# R7KA8T2AD register map
Vendor: Renesas Electronics Corporation; Series: RA8; File version: 1.10.02
CPU: CM85 r0p2, little endian, MPU, FPU, VTOR, 4 interrupt priority bits, 96 interrupts
Registers are 32-bit, read-write, reset 0x0 unless marked. A register's access mark holds for its fields unless they carry their own. Offsets are from the block's base; [hi:lo] are bit positions; <NAME> marks a mode.

## ULPT0
Base 0x40220000
Same registers: ULPT1 0x40220100, ULPT0_NS 0x50220000, ULPT1_NS 0x50220100
0x00 ULPTCNT reset 0xFFFFFFFF — ULPT Counter Register
  [31:0] ULPTCNT — Setting range : 0x00000000 to 0xFFFFFFFF
0x04 ULPTCMA reset 0xFFFFFFFF — ULPT Compare Match A Register
  [31:0] ULPTCMA — 32-bit Compare Match A Data
0x08 ULPTCMB reset 0xFFFFFFFF — ULPT Compare Match B Register
  [31:0] ULPTCMB — 32-bit Compare Match B Data
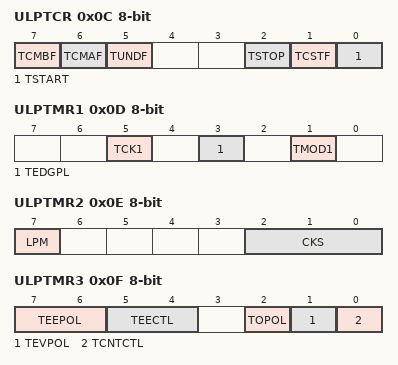
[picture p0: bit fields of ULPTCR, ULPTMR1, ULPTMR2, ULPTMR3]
0x0C ULPTCR 8-bit — ULPT Control Register
  [7] TCMBF — Compare Match B Flag
    0=Not matched (counter ≠ ULPTCMB[31:0]); 1=Matched (counter = ULPTCMB[31:0])
  [6] TCMAF — Compare Match A Flag
    0=Not matched (counter ≠ ULPTCMA[31:0]); 1=Matched (counter = ULPTCMA[31:0])
  [5] TUNDF — Underflow Flag
    0=No underflow occurred (counter ≠ 0x00000000); 1=Underflow occurred (counter = 0x00000000)
  [2] TSTOP wo — Counter Forcible Stop
    0=Writing is invalid; 1=Stop the counter forcibly
  [1] TCSTF ro — Counter Status Flag
    0=Counter stopped; 1=Counter running
  [0] TSTART — Counter Start
    0=Stop the counter; 1=Start the counter
0x0D ULPTMR1 8-bit — ULPT Mode Register 1
  [5] TCK1 — Count Source
    0=Divided clock specified by the ULPTMR2.CKS[2:0] bits (ULPTLCLK); 1=Divided clock specified by the ULPTMR2.CKS[2:0] bits (ULPTSCLK)
  [3] TEDGPL — ULPTEVIn Edge Polarity
    0=Either edge (rising); 1=Both edges
  [1] TMOD1 — Operating Mode
    0=Timer mode; 1=Event counter mode
0x0E ULPTMR2 8-bit — ULPT Mode Register 2
  [7] LPM — Low Power Mode
    0=Normal mode; 1=Low power mode
  [2:0] CKS — ULPTLCLK/ULPTSCLK Count Source Clock Division Ratio
    0=1/1; 1=1/2; 2=1/4; 3=1/8; 4=1/16; 5=1/32; 6=1/64; 7=1/128
0x0F ULPTMR3 8-bit — ULPT Mode Register 3
  [7:6] TEEPOL — ULPTEEn Edge Polarity Select
    0=Rising edge; 1=Falling edge; 2=Both edges
  [5:4] TEECTL — ULPTEEn Function Select
    0=Count enable mode; 2=Count start mode; 3=Count restart mode
  [2] TOPOL — ULPTOn Polarity Select
    0=Start the ULPTOn output when in low level; 1=Start the ULPTOn output when in high level
  [1] TEVPOL — ULPTEVIn Polarity Switch
    0=External event input (ULPTEVIn pin); 1=External event input (ULPTEVIn pin) in reverse
  [0] TCNTCTL — Count Function Select
    0=Continuous mode; 1=One-shot mode
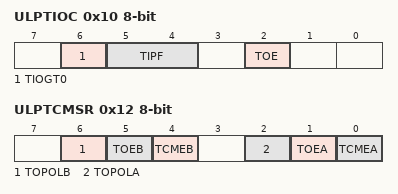
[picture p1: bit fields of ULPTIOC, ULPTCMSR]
0x10 ULPTIOC 8-bit — ULPT I/O Control Register
  [6] TIOGT0 — ULPTEVIn Count Control
    0=Always count external events; 1=Count external events while the ULPTEVIn pin is valid
  [5:4] TIPF — ULPTEVIn Input Filter
    0=No filter; 1=Filter sampling at PCLKB; 2=Filter sampling at PCLKB/8; 3=Filter sampling at PCLKB/32
  [2] TOE — ULPTOn Output Enable
    0=Disable the ULPTOn output; 1=Enable the ULPTOn output
0x11 ULPTISR 8-bit — ULPT Event Pin Select Register
  [2] RCCPSEL2 — ULPTEEn Polarity Select
    0=Count external events when low; 1=Count external events when high
0x12 ULPTCMSR 8-bit — ULPT Compare Match Function Select Register
  [6] TOPOLB — ULPTOBn Polarity Select
    0=Start the ULPTOBn output when low; 1=Start the ULPTOBn output when high
  [5] TOEB — ULPTOBn Output Enable
    0=Disable the ULPTOBn output; 1=Enable the ULPTOBn output
  [4] TCMEB — Compare Match B Register Enable
    0=Disable compare match B register; 1=Enable compare match B register
  [2] TOPOLA — ULPTOAn Polarity Select
    0=Start the ULPTOAn output when low; 1=Start the ULPTOAn output when high
  [1] TOEA — ULPTOAn Output Enable
    0=Disable the ULPTOAn output; 1=Enable the ULPTOAn output
  [0] TCMEA — Compare Match A Register Enable
    0=Disable compare match A register; 1=Enable compare match A register

## DAC0_B — 12-bit D/A converter
Base 0x40233000
Same registers: DAC1_B 0x40233100, DAC0_B_NS 0x50233000, DAC1_B_NS 0x50233100
0x00 DADR 16-bit — D/A Data Register
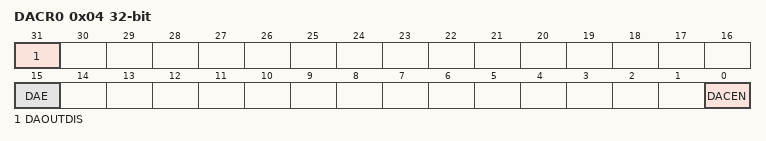
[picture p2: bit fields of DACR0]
0x04 DACR0 — D/A Control 0 Register
  [31] DAOUTDIS — Analog Output Disables
    0=The output to pin is enabled and the output to comparator is disabled; 1=The output to pin is disabled and the output to comparator is enabled
  [15] DAE — D/A Enable R/W
    0=Control D/A conversion of channels 0 and 1 individually; 1=Control D/A conversion of channels 0 and 1 collectively
  [0] DACEN — D/A Output Enable
    0=Disable analog output of channel n (DAn); 1=Enable D/A conversion of channel n (DAn)
0x08 DACR1 — D/A Control 1 Register
  [16] DPSEL — DADR Format Select R/W
    0=Right-justified format; 1=Left-justified format
0x0C DACR2 — D/A Control 2 Register
  [8] OFSSEL — DAC Operating Voltage Mode Selection
    0=Normal voltage mode (VREFH ≥ 2.7 V); 1=Low voltage mode (VREFH < 2.7 V)
